# STM32MP25_CM0P register map
File version: 1.0
CPU: CM0PLUS r0p1, little endian, MPU, no FPU, vendor SysTick, 8 interrupt priority bits
Registers are 32-bit, read-write, reset 0x0 unless marked. A register's access mark holds for its fields unless they carry their own. Offsets are from the block's base; lines under a group give offsets from that group; [hi:lo] are bit positions; {n}, {i} and the like mark numbered series; 'fields as' and 'values as' point back to an identical list; <NAME> marks a mode.

## Memory map
0x42080000 RIFSC size 0x1000 — RIFSC register block
0x44210000 PWR size 0x400 — PWR register block
0x46000000 RTC size 0x400 — RTC register block
0x46010000 TAMP size 0x400 — TAMP register block
0x46020000 SPI8 size 0x400 — SPI8 address block description
0x46030000 LPUART size 0x400 — LPUART address block description
0x46040000 I2C8 size 0x400 — I2C register block
0x46050000 LPTIM3 size 0x400 — LPTIM3 address block description
0x46060000 LPTIM4 size 0x400
0x46070000 LPTIM5 size 0xC — LPTIM5 address block description
0x46080000 I3C4 size 0x400 — I3C register block
0x46090000 IWDG5 size 0x400 — IWDG register block
0x460A0000 WWDG2 size 0x400 — WWDG2 address block description
0x46200000 GPIOZ size 0x1000 — Control of ioport Z
0x46210000 LPDMA size 0x1000 — LPDMA register block
0x46220000 ADF size 0x1000 — ADF register block
0x46230000 EXTI2 size 0x400 — EXTI2 address block description
0x46240000 HSEM size 0x400 — HSEM address block description
0x46250000 IPCC2 size 0x3F4 — IPCC2 address block description

## Interrupts
0 IWDG5 — Independent Watchdog 5 Early interrupt
1 WWDG2 — Window watchdog 2 early wakeup interrupt
2 TAMP — Tamper interrupt (include LSECSS interrupts)
5 EXTI2_L (EXTI2) — EXTI2 lines 0 to 7 interrupt
6 EXTI2_H (EXTI2) — EXTI2 lines 8 to 15 interrupt
7 LPDMA1_Channel0 (LPDMA) — LPDMA1 channel 0 interrupt
8 LPDMA1_Channel1 (LPDMA) — LPDMA1 channel 1 interrupt
9 LPDMA1_Channel2 (LPDMA) — LPDMA1 channel 2 interrupt
10 LPDMA1_Channel3 (LPDMA) — LPDMA1 channel 3 interrupt
11 LPUART1 (LPUART) — LPUART1 Global interrupt
12 SPI8 — SPI8 global interrupt
13 IPCC2_RX (IPCC2) — Mailbox nonsec Rx Occupied interrupt
14 IPCC2_TX (IPCC2) — Mailbox nonsec Tx Free interrupt
15 I2C8 — I2C8 global interrupt
16 I3C4 — I3C4 global interrupt
18 LPTIM3 — LPTIMER3 global interrupt
19 LPTIM4 — LPTIMER3 global interrupt
20 LPTIM5 — LPTIMER5 global interrupt
21 HSEM — HSEM semaphore non-secure interrupt
23 ADF1 (ADF) — ADF1 Filter interrupt
25 CPU1_SEV (EXTI2) — Cortex-A35 send event through EXTI2
26 CPU2_SEV (EXTI2) — Cortex-M33 send event through EXTI2

## IPCC2 — IPCC2 address block description
Base 0x46250000
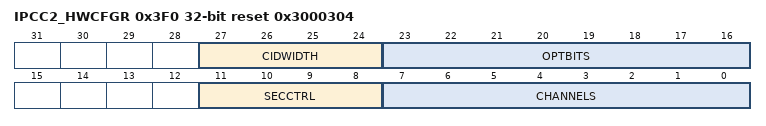
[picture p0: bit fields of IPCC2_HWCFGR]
0x3F0 IPCC2_HWCFGR ro reset 0x3000304 — IPCC hardware configuration register
  [27:24] CIDWIDTH — CID bit field width range 0 to 12. 1..12: CID filtering with CID bit field with 1..12 13..15: reserved
    0=No CID filtering
  [23:16] OPTBITS — reserved for future use
  [11:8] SECCTRL — security options, range 1 to 16.
    0=No security; 1=Security
  [7:0] CHANNELS — Number of channels per CPU supported by the IP, range 1 to 16

## WWDG2 — WWDG2 address block description
Base 0x460A0000
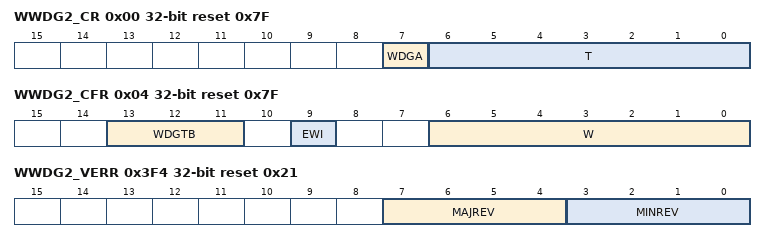
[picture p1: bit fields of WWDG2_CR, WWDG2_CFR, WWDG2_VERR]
0x00 WWDG2_CR reset 0x7F — WWDG control register
  [7] WDGA — Activation bit This bit is set by software and only cleared by hardware after a reset. When WDGA=1, the watchdog can generate a reset.
    0=Watchdog disabled; 1=Watchdog enabled
  [6:0] T — 7-bit counter (MSB to LSB) These bits contain the value of the watchdog counter, decremented every (4096 x 2<sup>WDGTB[2:0]</sup>) PCLK cycles. A reset is produced when it is decremented from 0x40 to 0x3F (T6 becomes cleared).
0x04 WWDG2_CFR reset 0x7F — WWDG configuration register
  [13:11] WDGTB — Timer base The timebase of the prescaler can be modified as follows:
    0=CK counter clock (PCLK div 4096) div 1; 1=CK counter clock (PCLK div 4096) div 2; 2=CK counter clock (PCLK div 4096) div 4; 3=CK counter clock (PCLK div 4096) div 8; 4=CK counter clock (PCLK div 4096) div 16; 5=CK counter clock (PCLK div 4096) div 32; 6=CK counter clock (PCLK div 4096) div 64; 7=CK counter clock (PCLK div 4096) div 128
  [9] EWI — Early wake-up interrupt enable Set by software and cleared by hardware after a reset. When set, an interrupt occurs whenever the counter reaches the value 0x40.
  [6:0] W — 7-bit window value These bits contain the window value to be compared with the down-counter.
0x08 WWDG2_SR — WWDG status register
  [0] EWIF — Early wake-up interrupt flag This bit is set by hardware when the counter has reached the value 0x40. It must be cleared by software by writing 0. Writing 1 has no effect. This bit is also set if the interrupt is not enabled.
0x3F0 WWDG2_HWCFGR ro reset 0x1000 — WWDG hardware configuration register
  [15:0] PREDIV — The watchdog clock is prescaled by 4096 (PREDIV[15:0]).
0x3F4 WWDG2_VERR ro reset 0x21 — WWDG version register
  [7:4] MAJREV — WWDG major revision
  [3:0] MINREV — WWDG minor revision
0x3F8 WWDG2_IPIDR ro reset 0x120051 — WWDG identification register
  [31:0] ID — WWDG peripheral identifier
0x3FC WWDG2_SIDR ro reset 0xA3C5DD01 — WWDG size identification register
  [31:0] SID — The address decoding range is 1 Kbyte

## Notices in the file
Copyright (c) 2024 STMicroelectronics.
SPDX-License-Identifier: Apache-2.0
Licensed under the Apache License, Version 2.0 (the "License");
you may not use this file except in compliance with the License.
You may obtain a copy of the License at
http://www.apache.org/licenses/LICENSE-2.0
Unless required by applicable law or agreed to in writing, software
distributed under the License is distributed on an "AS IS" BASIS,
WITHOUT WARRANTIES OR CONDITIONS OF ANY KIND, either express or implied.
See the License for the specific language governing permissions and
limitations under the License.
